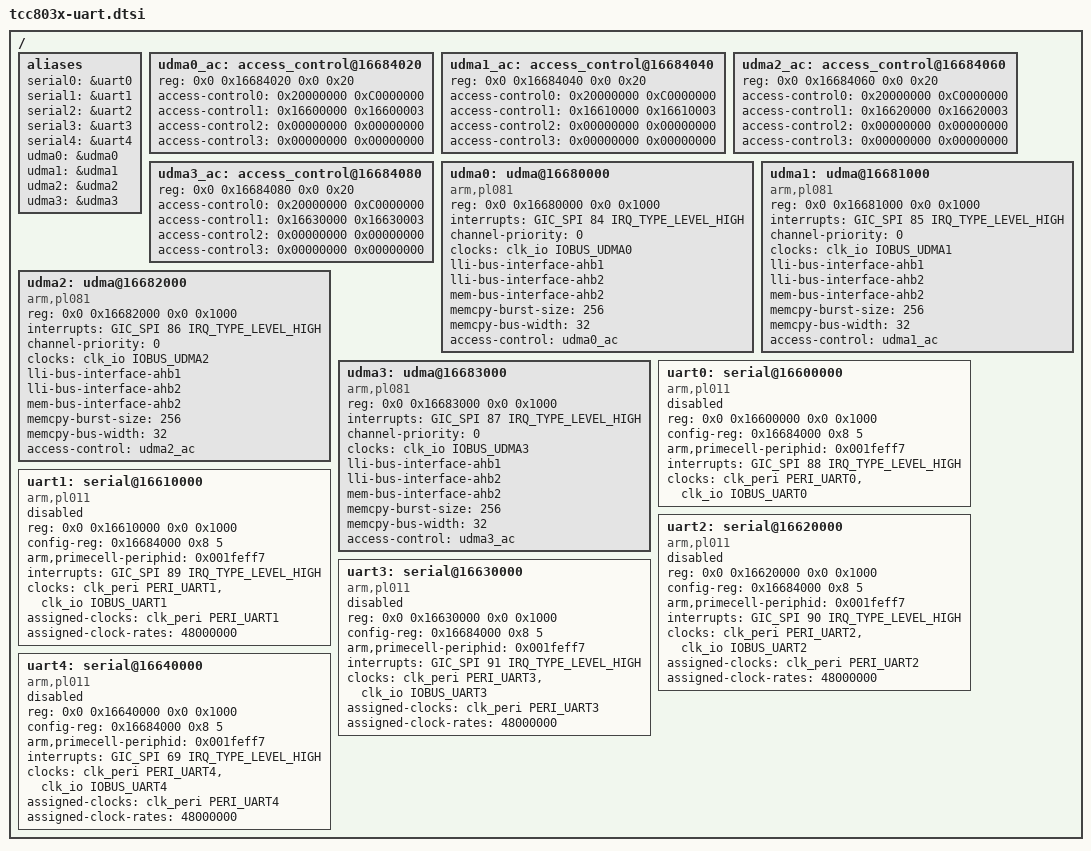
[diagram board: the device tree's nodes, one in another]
// SPDX-License-Identifier: (GPL-2.0-or-later OR MIT)
/*
 * Copyright (C) 2023 Telechips Inc.
 */

#include <dt-bindings/clock/telechips,tcc803x-clks.h>
#include <dt-bindings/interrupt-controller/arm-gic.h>

/ {
	aliases: aliases {
		serial0 = &uart0;
		serial1 = &uart1;
		serial2 = &uart2;
		serial3 = &uart3;
		serial4 = &uart4;
		udma0 = &udma0;
		udma1 = &udma1;
		udma2 = &udma2;
		udma3 = &udma3;
	};

	udma0_ac: access_control@16684020 {
		reg = <0x0 0x16684020 0x0 0x20>;
		access-control0 = <0x20000000 0xC0000000>; /* DRAM */
		access-control1 = <0x16600000 0x16600003>; /* UART 0 Data Register*/
		access-control2 = <0x00000000 0x00000000>;
		access-control3 = <0x00000000 0x00000000>;
	};

	udma1_ac: access_control@16684040 {
		reg = <0x0 0x16684040 0x0 0x20>;
		access-control0 = <0x20000000 0xC0000000>; /* DRAM */
		access-control1 = <0x16610000 0x16610003>; /* UART 1 Data Register*/
		access-control2 = <0x00000000 0x00000000>;
		access-control3 = <0x00000000 0x00000000>;
	};

	udma2_ac: access_control@16684060 {
		reg = <0x0 0x16684060 0x0 0x20>;
		access-control0 = <0x20000000 0xC0000000>; /* DRAM */
		access-control1 = <0x16620000 0x16620003>; /* UART 2 Data Register*/
		access-control2 = <0x00000000 0x00000000>;
		access-control3 = <0x00000000 0x00000000>;
	};

	udma3_ac: access_control@16684080 {
		reg = <0x0 0x16684080 0x0 0x20>;
		access-control0 = <0x20000000 0xC0000000>; /* DRAM */
		access-control1 = <0x16630000 0x16630003>; /* UART 3 Data Register*/
		access-control2 = <0x00000000 0x00000000>;
		access-control3 = <0x00000000 0x00000000>;
	};

	udma0: udma@16680000 {
		compatible = "arm,pl081", "arm,primecell";
		reg = <0x0 0x16680000 0x0 0x1000>;
		interrupts = <GIC_SPI 84 IRQ_TYPE_LEVEL_HIGH>;
		//dma-channels = <2>;
		//dma-requests = <32>;
		channel-priority = <0>;
		clocks = <&clk_io IOBUS_UDMA0>;
		clock-names = "apb_pclk";
		lli-bus-interface-ahb1;
		lli-bus-interface-ahb2;
		mem-bus-interface-ahb2;
		memcpy-burst-size = <256>;
		memcpy-bus-width = <32>;
		#dma-cells = <2>;
		access-control = <&udma0_ac>;
	};

	udma1: udma@16681000 {
		compatible = "arm,pl081", "arm,primecell";
		reg = <0x0 0x16681000 0x0 0x1000>;
		interrupts = <GIC_SPI 85 IRQ_TYPE_LEVEL_HIGH>;
		//dma-channels = <2>;
		//dma-requests = <32>;
		channel-priority = <0>;
		clocks = <&clk_io IOBUS_UDMA1>;
		clock-names = "apb_pclk";
		lli-bus-interface-ahb1;
		lli-bus-interface-ahb2;
		mem-bus-interface-ahb2;
		memcpy-burst-size = <256>;
		memcpy-bus-width = <32>;
		#dma-cells = <2>;
		access-control = <&udma1_ac>;
	};

	udma2: udma@16682000 {
		compatible = "arm,pl081", "arm,primecell";
		reg = <0x0 0x16682000 0x0 0x1000>;
		interrupts = <GIC_SPI 86 IRQ_TYPE_LEVEL_HIGH>;
		//dma-channels = <2>;
		//dma-requests = <32>;
		channel-priority = <0>;
		clocks = <&clk_io IOBUS_UDMA2>;
		clock-names = "apb_pclk";
		lli-bus-interface-ahb1;
		lli-bus-interface-ahb2;
		mem-bus-interface-ahb2;
		memcpy-burst-size = <256>;
		memcpy-bus-width = <32>;
		#dma-cells = <2>;
		access-control = <&udma2_ac>;
	};

	udma3: udma@16683000 {
		compatible = "arm,pl081", "arm,primecell";
		reg = <0x0 0x16683000 0x0 0x1000>;
		interrupts = <GIC_SPI 87 IRQ_TYPE_LEVEL_HIGH>;
		//dma-channels = <2>;
		//dma-requests = <32>;
		channel-priority = <0>;
		clocks = <&clk_io IOBUS_UDMA3>;
		clock-names = "apb_pclk";
		lli-bus-interface-ahb1;
		lli-bus-interface-ahb2;
		mem-bus-interface-ahb2;
		memcpy-burst-size = <256>;
		memcpy-bus-width = <32>;
		#dma-cells = <2>;
		access-control = <&udma3_ac>;
	};

	uart0: serial@16600000 {
		compatible = "arm,pl011", "arm,primecell";
		reg = <0x0 0x16600000 0x0 0x1000>;
		config-reg = <0x16684000 0x8 5>;
		arm,primecell-periphid = <0x001feff7>;
		interrupts = <GIC_SPI 88 IRQ_TYPE_LEVEL_HIGH>;
		clocks = <&clk_peri PERI_UART0>, <&clk_io IOBUS_UART0>;
		clock-names = "uartclk", "apb_pclk";
		status = "disabled";
	};

	uart1: serial@16610000 {
		compatible = "arm,pl011", "arm,primecell";
		reg = <0x0 0x16610000 0x0 0x1000>;
		config-reg = <0x16684000 0x8 5>;
		arm,primecell-periphid = <0x001feff7>;
		interrupts = <GIC_SPI 89 IRQ_TYPE_LEVEL_HIGH>;
		clocks = <&clk_peri PERI_UART1>, <&clk_io IOBUS_UART1>;
		clock-names = "uartclk", "apb_pclk";
		assigned-clocks = <&clk_peri PERI_UART1>;
		assigned-clock-rates = <48000000>;
		status = "disabled";
	};

	uart2: serial@16620000 {
		compatible = "arm,pl011", "arm,primecell";
		reg = <0x0 0x16620000 0x0 0x1000>;
		config-reg = <0x16684000 0x8 5>;
		arm,primecell-periphid = <0x001feff7>;
		interrupts = <GIC_SPI 90 IRQ_TYPE_LEVEL_HIGH>;
		clocks = <&clk_peri PERI_UART2>, <&clk_io IOBUS_UART2>;
		clock-names = "uartclk", "apb_pclk";
		assigned-clocks = <&clk_peri PERI_UART2>;
		assigned-clock-rates = <48000000>;
		status = "disabled";
	};

	uart3: serial@16630000 {
		compatible = "arm,pl011", "arm,primecell";
		reg = <0x0 0x16630000 0x0 0x1000>;
		config-reg = <0x16684000 0x8 5>;
		arm,primecell-periphid = <0x001feff7>;
		interrupts = <GIC_SPI 91 IRQ_TYPE_LEVEL_HIGH>;
		clocks = <&clk_peri PERI_UART3>, <&clk_io IOBUS_UART3>;
		clock-names = "uartclk", "apb_pclk";
		assigned-clocks = <&clk_peri PERI_UART3>;
		assigned-clock-rates = <48000000>;
		status = "disabled";
	};

	uart4: serial@16640000 {
		compatible = "arm,pl011", "arm,primecell";
		reg = <0x0 0x16640000 0x0 0x1000>;
		config-reg = <0x16684000 0x8 5>;
		arm,primecell-periphid = <0x001feff7>;
		interrupts = <GIC_SPI 69 IRQ_TYPE_LEVEL_HIGH>;
		clocks = <&clk_peri PERI_UART4>, <&clk_io IOBUS_UART4>;
		clock-names = "uartclk", "apb_pclk";
		assigned-clocks = <&clk_peri PERI_UART4>;
		assigned-clock-rates = <48000000>;
		status = "disabled";
	};
};
